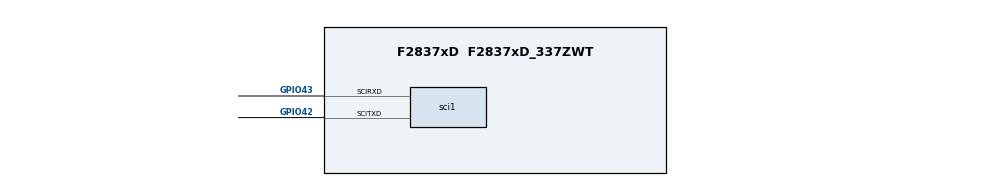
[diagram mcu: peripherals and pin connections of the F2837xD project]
/**
 * @cliArgs --board "/boards/LAUNCHXL_F28379D" --device "F2837xD" --part "F2837xD_337ZWT" --package "F2837xD_337ZWT" --context "CPU1" --product "C2000WARE@26.00.00.00"
 * @versions {"tool":"1.27.0+4565"}
 */

/**
 * Import the modules used in this configuration.
 */
const sci  = scripting.addModule("/driverlib/sci.js", {}, false);
const sci1 = sci.addInstance();

/**
 * Write custom configuration values to the imported modules.
 */
sci1.$name                      = "SCI0";
sci1.selectRegisteredInterrupts = ["registerRxInt"];
sci1.enabledFIFOInterrupts      = ["SCI_INT_RXFF"];
sci1.rxFifo                     = "SCI_FIFO_RX2";
sci1.sci.scirxdPin.$assign      = "GPIO43";
sci1.sci.scitxdPin.$assign      = "GPIO42";
sci1.rxQual.$name               = "myGPIOQUAL0";
sci1.txQual.$name               = "myGPIOQUAL1";
sci1.sciRXInt.enableInterrupt   = true;

/**
 * Pinmux solution for unlocked pins/peripherals. This ensures that minor changes to the automatic solver in a future
 * version of the tool will not impact the pinmux you originally saw.  These lines can be completely deleted in order to
 * re-solve from scratch.
 */
sci1.sci.$suggestSolution = "SCIA";
